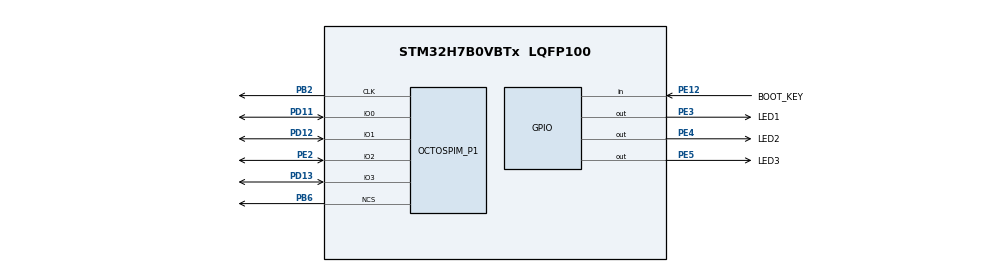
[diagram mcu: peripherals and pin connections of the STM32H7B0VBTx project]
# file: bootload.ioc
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CORTEX_M7.CPU_ICache=Enabled
Mcu.Family=STM32H7
Mcu.Name=STM32H7B0VBTx
Mcu.Package=LQFP100
NVIC.PriorityGroup=NVIC_PRIORITYGROUP_4
OCTOSPI1.ChipSelectHighTime=5
OCTOSPI1.ClockPrescaler=4
OCTOSPI1.DeviceSize=23
OCTOSPI1.FifoThreshold=8
PB2.GPIO_Speed_High_Default=GPIO_SPEED_FREQ_VERY_HIGH
PB2.Mode=O1_P1_CLK
PB2.Signal=OCTOSPIM_P1_CLK
PB6.GPIO_PuPd=GPIO_PULLUP
PB6.GPIO_Speed_High_Default=GPIO_SPEED_FREQ_VERY_HIGH
PB6.Mode=OCTOSPI1_Port1_NCS
PB6.Signal=OCTOSPIM_P1_NCS
PD11.GPIO_Speed_High_Default=GPIO_SPEED_FREQ_VERY_HIGH
PD11.Mode=OCTOSPI1_IOL_Port1L
PD11.Signal=OCTOSPIM_P1_IO0
PD12.GPIO_Speed_High_Default=GPIO_SPEED_FREQ_VERY_HIGH
PD12.Mode=OCTOSPI1_IOL_Port1L
PD12.Signal=OCTOSPIM_P1_IO1
PD13.GPIO_Speed_High_Default=GPIO_SPEED_FREQ_VERY_HIGH
PD13.Mode=OCTOSPI1_IOL_Port1L
PD13.Signal=OCTOSPIM_P1_IO3
PE12.GPIO_Label=BOOT_KEY
PE12.GPIO_PuPd=GPIO_PULLUP
PE12.Signal=GPIO_Input
PE2.GPIO_Speed_High_Default=GPIO_SPEED_FREQ_VERY_HIGH
PE2.Mode=OCTOSPI1_IOL_Port1L
PE2.Signal=OCTOSPIM_P1_IO2
PE3.GPIO_Label=LED1
PE3.Signal=GPIO_Output
PE4.GPIO_Label=LED2
PE4.Signal=GPIO_Output
PE5.GPIO_Label=LED3
PE5.Signal=GPIO_Output
PH0-OSC_IN.Mode=HSE-External-Clock-Source
PH0-OSC_IN.Signal=RCC_OSC_IN
ProjectManager.HeapSize=0x200
ProjectManager.StackSize=0x400
ProjectManager.TargetToolchain=STM32CubeIDE
RCC.ADCFreq_Value=129000000
RCC.APB1Freq_Value=140000000
RCC.APB2Freq_Value=140000000
RCC.APB3Freq_Value=140000000
RCC.APB4Freq_Value=140000000
RCC.CDPPRE=RCC_APB3_DIV2
RCC.CDPPRE1=RCC_APB1_DIV2
RCC.CDPPRE2=RCC_APB2_DIV2
RCC.CortexFreq_Value=280000000
RCC.D1PPRE=RCC_APB3_DIV2
RCC.D2PPRE1=RCC_APB1_DIV2
RCC.D2PPRE2=RCC_APB2_DIV2
RCC.D3PPRE=RCC_APB4_DIV2
RCC.DIVM1=16
RCC.DIVN1=140
RCC.DIVQ1=20
RCC.HCLKFreq_Value=280000000
RCC.HSE_VALUE=26000000
RCC.SRDPPRE=RCC_APB4_DIV2
RCC.SYSCLKFreq_VALUE=280000000
RCC.SYSCLKSource=RCC_SYSCLKSOURCE_PLLCLK
RCC.USBCLockSelection=RCC_USBCLKSOURCE_HSI48
RCC.USBFreq_Value=48000000
VP_MBEDTLS_VS_MBEDTLS.Mode=Enabled
VP_OCTOSPI1_VS_quad.Mode=quad_mode
board=custom

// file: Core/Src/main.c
/* USER CODE BEGIN Header */
/**
  ******************************************************************************
  * @file           : main.c
  * @brief          : Main program body
  ******************************************************************************
  * @attention
  *
  * <h2><center>&copy; Copyright (c) 2020 STMicroelectronics.
  * All rights reserved.</center></h2>
  *
  * This software component is licensed by ST under BSD 3-Clause license,
  * the "License"; You may not use this file except in compliance with the
  * License. You may obtain a copy of the License at:
  *                        opensource.org/licenses/BSD-3-Clause
  *
  ******************************************************************************
  */
/* USER CODE END Header */
#include "main.h"
#include "mbedtls.h"
#include "octospi.h"
#include "gpio.h"

void SystemClock_Config(void);
/* USER CODE BEGIN PFP */
void doBoot(void);
/* USER CODE END PFP */

int main(void)
{

  /* Enable I-Cache---------------------------------------------------------*/
  SCB_EnableICache();

  /* MCU Configuration--------------------------------------------------------*/

  /* Reset of all peripherals, Initializes the Flash interface and the Systick. */
  HAL_Init();

  /* Configure the system clock */
  SystemClock_Config();

  /* Initialize all configured peripherals */
  MX_GPIO_Init();
  MX_MBEDTLS_Init();
  MX_OCTOSPI1_Init();
  /* USER CODE BEGIN 2 */
  doBoot();
//  sfud_init();
  /* USER CODE END 2 */

  /* Infinite loop */
  while (1)
  {

  }
}

void SystemClock_Config(void)
{

  /*AXI clock gating */
  RCC->CKGAENR = 0xFFFFFFFF;

  LL_FLASH_SetLatency(LL_FLASH_LATENCY_7);
  while(LL_FLASH_GetLatency()!= LL_FLASH_LATENCY_7)
  {
  }
  LL_PWR_ConfigSupply(LL_PWR_LDO_SUPPLY);
  LL_PWR_SetRegulVoltageScaling(LL_PWR_REGU_VOLTAGE_SCALE0);
  LL_RCC_HSI_Enable();

   /* Wait till HSI is ready */
  while(LL_RCC_HSI_IsReady() != 1)
  {

  }
  LL_RCC_HSI_SetCalibTrimming(32);
  LL_RCC_HSI_SetDivider(LL_RCC_HSI_DIV1);
  LL_RCC_PLL_SetSource(LL_RCC_PLLSOURCE_HSI);
  LL_RCC_PLL1P_Enable();
  LL_RCC_PLL1_SetVCOInputRange(LL_RCC_PLLINPUTRANGE_4_8);
  LL_RCC_PLL1_SetVCOOutputRange(LL_RCC_PLLVCORANGE_WIDE);
  LL_RCC_PLL1_SetM(16);
  LL_RCC_PLL1_SetN(140);
  LL_RCC_PLL1_SetP(2);
  LL_RCC_PLL1_SetQ(20);
  LL_RCC_PLL1_SetR(2);
  LL_RCC_PLL1_Enable();

   /* Wait till PLL is ready */
  while(LL_RCC_PLL1_IsReady() != 1)
  {
  }

   /* Intermediate AHB prescaler 2 when target frequency clock is higher than 80 MHz */
   LL_RCC_SetAHBPrescaler(LL_RCC_AHB_DIV_2);

  LL_RCC_SetSysClkSource(LL_RCC_SYS_CLKSOURCE_PLL1);

   /* Wait till System clock is ready */
  while(LL_RCC_GetSysClkSource() != LL_RCC_SYS_CLKSOURCE_STATUS_PLL1)
  {

  }
  LL_RCC_SetAHBPrescaler(LL_RCC_AHB_DIV_1);
  LL_RCC_SetAPB1Prescaler(LL_RCC_APB1_DIV_2);
  LL_RCC_SetAPB2Prescaler(LL_RCC_APB2_DIV_2);
  LL_RCC_SetAPB3Prescaler(LL_RCC_APB3_DIV_2);
  LL_RCC_SetAPB4Prescaler(LL_RCC_APB4_DIV_2);
  LL_SetSystemCoreClock(280000000);

   /* Update the time base */
  if (HAL_InitTick (TICK_INT_PRIORITY) != HAL_OK)
  {
    Error_Handler();
  }
}

void Error_Handler(void)
{
}
